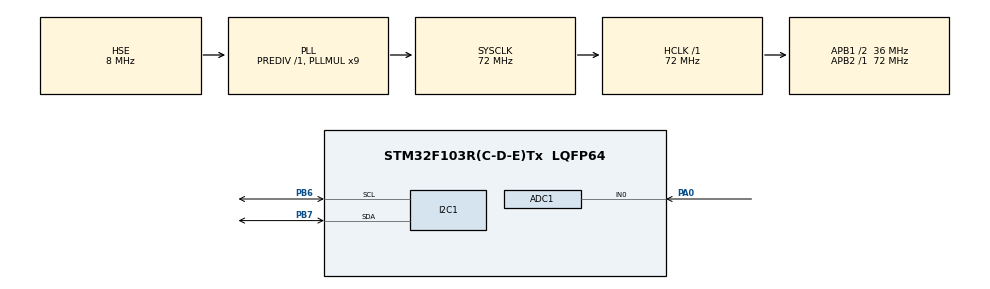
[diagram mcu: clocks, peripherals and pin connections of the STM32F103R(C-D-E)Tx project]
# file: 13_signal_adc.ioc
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ADC1.Channel-0\#ChannelRegularConversion=ADC_CHANNEL_0
ADC1.NbrOfConversionFlag=1
ADC1.Rank-0\#ChannelRegularConversion=1
ADC1.SamplingTime-0\#ChannelRegularConversion=ADC_SAMPLETIME_1CYCLE_5
ADC1.master=1
FREERTOS.Tasks01=ADC,24,256,ADC_Entry,Default,NULL,Dynamic,NULL,NULL
I2C1.I2C_Mode=I2C_Fast
Mcu.Family=STM32F1
Mcu.Name=STM32F103R(C-D-E)Tx
Mcu.Package=LQFP64
NVIC.PriorityGroup=NVIC_PRIORITYGROUP_4
NVIC.TIM7_IRQn=true\:15\:0\:false\:false\:true\:false\:false\:true\:true
NVIC.TimeBase=TIM7_IRQn
NVIC.TimeBaseIP=TIM7
PA0-WKUP.Signal=ADCx_IN0
PA13.Mode=Serial_Wire
PA13.Signal=SYS_JTMS-SWDIO
PA14.Mode=Serial_Wire
PA14.Signal=SYS_JTCK-SWCLK
PB6.Mode=I2C
PB6.Signal=I2C1_SCL
PB7.Mode=I2C
PB7.Signal=I2C1_SDA
PC14-OSC32_IN.Mode=LSE-External-Oscillator
PC14-OSC32_IN.Signal=RCC_OSC32_IN
PC15-OSC32_OUT.Mode=LSE-External-Oscillator
PC15-OSC32_OUT.Signal=RCC_OSC32_OUT
PD0-OSC_IN.Mode=HSE-External-Oscillator
PD0-OSC_IN.Signal=RCC_OSC_IN
PD1-OSC_OUT.Mode=HSE-External-Oscillator
PD1-OSC_OUT.Signal=RCC_OSC_OUT
ProjectManager.HeapSize=0x200
ProjectManager.StackSize=0x400
ProjectManager.TargetToolchain=MDK-ARM V5.32
RCC.ADCPresc=RCC_ADCPCLK2_DIV6
RCC.AHBFreq_Value=72000000
RCC.APB1CLKDivider=RCC_HCLK_DIV2
RCC.APB1Freq_Value=36000000
RCC.APB1TimFreq_Value=72000000
RCC.APB2Freq_Value=72000000
RCC.APB2TimFreq_Value=72000000
RCC.HCLKFreq_Value=72000000
RCC.PLLMUL=RCC_PLL_MUL9
RCC.PLLSourceVirtual=RCC_PLLSOURCE_HSE
RCC.SYSCLKFreq_VALUE=72000000
RCC.SYSCLKSource=RCC_SYSCLKSOURCE_PLLCLK
RCC.USBFreq_Value=72000000
SH.ADCx_IN0.0=ADC1_IN0,IN0
VP_FREERTOS_VS_CMSIS_V2.Mode=CMSIS_V2
VP_SYS_VS_tim7.Mode=TIM7
board=custom

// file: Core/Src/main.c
/* USER CODE BEGIN Header */
/**
  ******************************************************************************
  * @file           : main.c
  * @brief          : Main program body
  ******************************************************************************
  * @attention
  *
  * Copyright (c) 2024 STMicroelectronics.
  * All rights reserved.
  *
  * This software is licensed under terms that can be found in the LICENSE file
  * in the root directory of this software component.
  * If no LICENSE file comes with this software, it is provided AS-IS.
  *
  ******************************************************************************
  */
/* USER CODE END Header */
#include "main.h"
#include "cmsis_os.h"
#include "adc.h"
#include "i2c.h"
#include "gpio.h"

void SystemClock_Config(void);
void MX_FREERTOS_Init(void);

int main(void)
{

  /* MCU Configuration--------------------------------------------------------*/

  /* Reset of all peripherals, Initializes the Flash interface and the Systick. */
  HAL_Init();

  /* Configure the system clock */
  SystemClock_Config();

  /* Initialize all configured peripherals */
  MX_GPIO_Init();
  MX_I2C1_Init();
  MX_ADC1_Init();

  /* Init scheduler */
  osKernelInitialize();

  /* Call init function for freertos objects (in freertos.c) */
  MX_FREERTOS_Init();

  /* Start scheduler */
  osKernelStart();

  /* We should never get here as control is now taken by the scheduler */
  /* Infinite loop */
  while (1)
  {

  }
}

void SystemClock_Config(void)
{
  RCC_OscInitTypeDef RCC_OscInitStruct = {0};
  RCC_ClkInitTypeDef RCC_ClkInitStruct = {0};
  RCC_PeriphCLKInitTypeDef PeriphClkInit = {0};

  /** Initializes the RCC Oscillators according to the specified parameters
  * in the RCC_OscInitTypeDef structure.
  */
  RCC_OscInitStruct.OscillatorType = RCC_OSCILLATORTYPE_HSE;
  RCC_OscInitStruct.HSEState = RCC_HSE_ON;
  RCC_OscInitStruct.HSEPredivValue = RCC_HSE_PREDIV_DIV1;
  RCC_OscInitStruct.HSIState = RCC_HSI_ON;
  RCC_OscInitStruct.PLL.PLLState = RCC_PLL_ON;
  RCC_OscInitStruct.PLL.PLLSource = RCC_PLLSOURCE_HSE;
  RCC_OscInitStruct.PLL.PLLMUL = RCC_PLL_MUL9;
  if (HAL_RCC_OscConfig(&RCC_OscInitStruct) != HAL_OK)
  {
    Error_Handler();
  }

  /** Initializes the CPU, AHB and APB buses clocks
  */
  RCC_ClkInitStruct.ClockType = RCC_CLOCKTYPE_HCLK|RCC_CLOCKTYPE_SYSCLK
                              |RCC_CLOCKTYPE_PCLK1|RCC_CLOCKTYPE_PCLK2;
  RCC_ClkInitStruct.SYSCLKSource = RCC_SYSCLKSOURCE_PLLCLK;
  RCC_ClkInitStruct.AHBCLKDivider = RCC_SYSCLK_DIV1;
  RCC_ClkInitStruct.APB1CLKDivider = RCC_HCLK_DIV2;
  RCC_ClkInitStruct.APB2CLKDivider = RCC_HCLK_DIV1;

  if (HAL_RCC_ClockConfig(&RCC_ClkInitStruct, FLASH_LATENCY_2) != HAL_OK)
  {
    Error_Handler();
  }
  PeriphClkInit.PeriphClockSelection = RCC_PERIPHCLK_ADC;
  PeriphClkInit.AdcClockSelection = RCC_ADCPCLK2_DIV6;
  if (HAL_RCCEx_PeriphCLKConfig(&PeriphClkInit) != HAL_OK)
  {
    Error_Handler();
  }
}

void HAL_TIM_PeriodElapsedCallback(TIM_HandleTypeDef *htim)
{
  if (htim->Instance == TIM7) {
    HAL_IncTick();
  }
}

void Error_Handler(void)
{
  __disable_irq();
  while (1)
  {
  }
}

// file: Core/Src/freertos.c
/* USER CODE BEGIN Header */
/**
  ******************************************************************************
  * File Name          : freertos.c
  * Description        : Code for freertos applications
  ******************************************************************************
  * @attention
  *
  * Copyright (c) 2024 STMicroelectronics.
  * All rights reserved.
  *
  * This software is licensed under terms that can be found in the LICENSE file
  * in the root directory of this software component.
  * If no LICENSE file comes with this software, it is provided AS-IS.
  *
  ******************************************************************************
  */
/* USER CODE END Header */

#include "FreeRTOS.h"
#include "task.h"
#include "main.h"
#include "cmsis_os.h"

/* USER CODE BEGIN Includes */
#include "oled.h"
#include "adc.h"
/* USER CODE END Includes */

/* USER CODE BEGIN Variables */
uint16_t ADValue;
float Voltage;
/* USER CODE END Variables */
/* Definitions for ADC */
osThreadId_t ADCHandle;
const osThreadAttr_t ADC_attributes = {
  .name = "ADC",
  .stack_size = 256 * 4,
  .priority = (osPriority_t) osPriorityNormal,
};

void ADC_Entry(void *argument);

void MX_FREERTOS_Init(void); /* (MISRA C 2004 rule 8.1) */

void MX_FREERTOS_Init(void) {

  /* Create the thread(s) */
  /* creation of ADC */
  ADCHandle = osThreadNew(ADC_Entry, NULL, &ADC_attributes);

}

void ADC_Entry(void *argument)
{
  /* USER CODE BEGIN ADC_Entry */
  OLED_Init();
  OLED_Display_On();
  OLED_Clear();
  OLED_ShowString(0,0,"ADValue:",16,0);
  OLED_ShowString(0,2,"Voltage:",16,0);
  HAL_ADC_Start(&hadc1);
  /* Infinite loop */
  for(;;)
  {
    if(HAL_ADC_PollForConversion(&hadc1, 100) == HAL_OK)
    {
      ADValue = HAL_ADC_GetValue(&hadc1);
      HAL_ADC_Start(&hadc1);
    }
    Voltage = ADValue * 3.3 / 4096;
    OLED_ShowNum(64,0,ADValue,6,16,0);
    OLED_Showdecimal(64,2,Voltage,2,2,16,0);
    osDelay(100);
  }
  /* USER CODE END ADC_Entry */
}
